VERSION ""

NS_ :

BS_:

BU_: Device Host
VAL_TABLE_ vtSysIgnition 3 "NA" 2 "RESERVED" 1 "ON" 0 "OFF" ;
VAL_TABLE_ vtSysReady 3 "NA" 2 "RESERVED" 1 "READY" 0 "NOT_READY" ;
VAL_TABLE_ vtDtsSysSt 3 "NA" 2 "ERROR" 1 "ON_OK" 0 "OFF" ;
VAL_TABLE_ vtDtsPedlSw 3 "Not available" 2 "Error" 1 "Pedal Depressed" 0 "Pedal Released" ;
VAL_TABLE_ vtOnOff 3 "Not available" 2 "Error" 1 "On" 0 "Off" ;
VAL_TABLE_ vAction_t 3 "va_Take_no_action" 2 "va_Reserved" 1 "va_On" 0 "va_Off" ;
VAL_TABLE_ vtDtsVehDirMov 3 "NA" 2 "REVERSE" 1 "FORWARD" 0 "STANDSTILL" ;

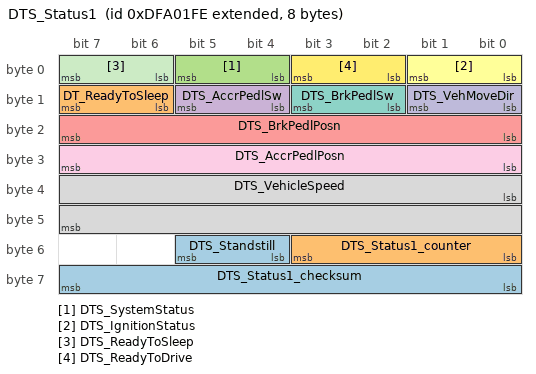
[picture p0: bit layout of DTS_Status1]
BO_ 2381971966 DTS_Status1: 8 Vector__XXX
 SG_ DTS_Standstill : 52|2@1+ (1,0) [0|3] "" Vector__XXX
 SG_ DT_ReadyToSleep : 14|2@1+ (1,0) [0|3] "" Vector__XXX
 SG_ DTS_SystemStatus : 4|2@1+ (1,0) [0|3] "" Vector__XXX
 SG_ DTS_AccrPedlSw : 12|2@1+ (1,0) [0|3] "" Vector__XXX
 SG_ DTS_BrkPedlPosn : 16|8@1+ (0.5,0) [0|127.5] "%" Vector__XXX
 SG_ DTS_IgnitionStatus : 0|2@1+ (1,0) [0|3] "" Vector__XXX
 SG_ DTS_BrkPedlSw : 10|2@1+ (1,0) [0|3] "" Vector__XXX
 SG_ DTS_VehicleSpeed : 32|16@1+ (0.01,-300) [-300|355.35] "km/h" Vector__XXX
 SG_ DTS_AccrPedlPosn : 24|8@1+ (0.4,0) [0|102] "%" Vector__XXX
 SG_ DTS_VehMoveDir : 8|2@1+ (1,0) [0|3] "" Vector__XXX
 SG_ DTS_ReadyToSleep : 6|2@1+ (1,0) [0|3] "" Vector__XXX
 SG_ DTS_ReadyToDrive : 2|2@1+ (1,0) [0|3] "" Vector__XXX
 SG_ DTS_Status1_checksum : 56|8@1+ (1,0) [0|255] "" Vector__XXX
 SG_ DTS_Status1_counter : 48|4@1+ (1,0) [0|15] "" Vector__XXX

CM_ "Arrival Drivetrain Controller Database.
$DBC storage: //depot/auto/dbc/Software_Modules/Drivetrain_Controller/ArrivalDTC/ $
$Change: 0 $
$DateTime: 2020/11/02 14:30:00 $
$Revision: #1 $
$Author: lyamin@arrival.com $
";
CM_ BO_ 2381971966 "Message with general information about current Drivetrain System state";
CM_ SG_ 2381971966 DTS_Standstill "Is the vehicle stationary or not?";
CM_ SG_ 2381971966 DT_ReadyToSleep "IDU readiness flag";
CM_ SG_ 2381971966 DTS_SystemStatus "Drivetrain readiness flag";
CM_ SG_ 2381971966 DTS_AccrPedlSw "is accelerator pedal pressed";
CM_ SG_ 2381971966 DTS_BrkPedlPosn "is brake pedal pressed";
CM_ SG_ 2381971966 DTS_IgnitionStatus "KL15 Ignition line state";
CM_ SG_ 2381971966 DTS_BrkPedlSw "Drivetrain system status";
CM_ SG_ 2381971966 DTS_VehicleSpeed "Signed Vehicle Speed";
CM_ SG_ 2381971966 DTS_VehMoveDir "Vehicle Directionv Movement state";
CM_ SG_ 2381971966 DTS_ReadyToSleep "Drivetrain readiness flag";
CM_ SG_ 2381971966 DTS_ReadyToDrive "Drivetrain readiness flag";
BA_DEF_  "BusType" STRING ;
BA_DEF_  "DBName" STRING ;
BA_DEF_  "DatabaseVersion" STRING ;
BA_DEF_ BO_  "GenMsgCycleTime" INT 0 3600000;
BA_DEF_ BO_  "GenMsgILSupport" ENUM  "No","Yes";
BA_DEF_ BO_  "GenMsgRequestable" INT 0 1;
BA_DEF_ BO_  "GenMsgSendType" ENUM  "cyclic","NotUsed","NotUsed","NotUsed","NotUsed","NotUsed","NotUsed","IfActive","noMsgSendType";
BA_DEF_ SG_  "GenSigEVName" STRING ;
BA_DEF_ SG_  "GenSigILSupport" ENUM  "No","Yes";
BA_DEF_ SG_  "GenSigSendType" ENUM  "Cyclic","OnWrite","OnWriteWithRepetition","OnChange","OnChangeWithRepetition","IfActive","IfActiveWithRepetition","NoSigSendType";
BA_DEF_ SG_  "GenSigStartValue" INT 0 2147483647;
BA_DEF_ BU_  "NmStationAddress" INT 0 255;
BA_DEF_  "ProtocolType" STRING ;
BA_DEF_  "SAE_J1939_21_SpecVersion" STRING ;
BA_DEF_  "SAE_J1939_71_SpecVersion" STRING ;
BA_DEF_  "SAE_J1939_73_SpecVersion" STRING ;
BA_DEF_  "SAE_J1939_75_SpecVersion" STRING ;
BA_DEF_  "SAE_J1939_81_SpecVersion" STRING ;
BA_DEF_  "SAE_J1939_DA_SpecVersion" STRING ;
BA_DEF_ SG_  "SigType" ENUM  "Default","Range","RangeSigned","ASCII","Discrete","Control","ReferencePGN","DTC","StringDelimiter","StringLength","StringLengthControl","MessageCounter","MessageChecksum";
BA_DEF_ BO_  "VFrameFormat" ENUM  "StandardCAN","ExtendedCAN","reserved","J1939PG","reserved","reserved","reserved","reserved","reserved","reserved","reserved","reserved","reserved","reserved","StandardCAN_FD","ExtendedCAN_FD";
BA_DEF_DEF_  "BusType" "";
BA_DEF_DEF_  "DBName" "";
BA_DEF_DEF_  "DatabaseVersion" "";
BA_DEF_DEF_  "GenMsgCycleTime" 0;
BA_DEF_DEF_  "GenMsgILSupport" "Yes";
BA_DEF_DEF_  "GenMsgRequestable" 1;
BA_DEF_DEF_  "GenMsgSendType" "noMsgSendType";
BA_DEF_DEF_  "GenSigEVName" "Env@Nodename_@Signame";
BA_DEF_DEF_  "GenSigILSupport" "Yes";
BA_DEF_DEF_  "GenSigSendType" "NoSigSendType";
BA_DEF_DEF_  "GenSigStartValue" 0;
BA_DEF_DEF_  "NmStationAddress" 254;
BA_DEF_DEF_  "ProtocolType" "";
BA_DEF_DEF_  "SAE_J1939_21_SpecVersion" "";
BA_DEF_DEF_  "SAE_J1939_71_SpecVersion" "";
BA_DEF_DEF_  "SAE_J1939_73_SpecVersion" "";
BA_DEF_DEF_  "SAE_J1939_75_SpecVersion" "";
BA_DEF_DEF_  "SAE_J1939_81_SpecVersion" "";
BA_DEF_DEF_  "SAE_J1939_DA_SpecVersion" "";
BA_DEF_DEF_  "SigType" "Default";
BA_DEF_DEF_  "VFrameFormat" "J1939PG";
BA_ "SAE_J1939_DA_SpecVersion" "2015-01";
BA_ "SAE_J1939_81_SpecVersion" "2012-05";
BA_ "SAE_J1939_75_SpecVersion" "2012-05";
BA_ "SAE_J1939_73_SpecVersion" "2012-10";
BA_ "SAE_J1939_71_SpecVersion" "2012-10";
BA_ "SAE_J1939_21_SpecVersion" "2006-10";
BA_ "ProtocolType" "J1939";
BA_ "DatabaseVersion" "1.0";
BA_ "BusType" "CAN";
BA_ "DBName" "DTS_Status1";
BA_ "GenMsgCycleTime" BO_ 2381971966 50;
BA_ "GenMsgSendType" BO_ 2381971966 0;
BA_ "SigType" SG_ 2381971966 DTS_BrkPedlPosn 1;
BA_ "SigType" SG_ 2381971966 DTS_VehicleSpeed 1;
BA_ "GenSigStartValue" SG_ 2381971966 DTS_VehicleSpeed 30000;
BA_ "SigType" SG_ 2381971966 DTS_AccrPedlPosn 1;
BA_ "SigType" SG_ 2381971966 DTS_Status1_checksum 12;
BA_ "GenSigSendType" SG_ 2381971966 DTS_Status1_checksum 0;
BA_ "GenSigSendType" SG_ 2381971966 DTS_Status1_counter 0;
BA_ "SigType" SG_ 2381971966 DTS_Status1_counter 11;
VAL_ 2381971966 DTS_Standstill 3 "NA" 2 "RESERVE" 1 "MOVING" 0 "STANDSTILL" ;
VAL_ 2381971966 DT_ReadyToSleep 3 "NA" 2 "RESERVED" 1 "READY" 0 "NOT_READY" ;
VAL_ 2381971966 DTS_SystemStatus 3 "Not available" 2 "Error" 1 "On" 0 "Off" ;
VAL_ 2381971966 DTS_AccrPedlSw 3 "Not available" 2 "Error" 1 "Pedal Depressed" 0 "Pedal Released" ;
VAL_ 2381971966 DTS_IgnitionStatus 3 "NA" 2 "RESERVED" 1 "ON" 0 "OFF" ;
VAL_ 2381971966 DTS_BrkPedlSw 3 "Not available" 2 "Error" 1 "Pedal Depressed" 0 "Pedal Released" ;
VAL_ 2381971966 DTS_VehMoveDir 3 "NA" 2 "REVERSE" 1 "FORWARD" 0 "STANDSTILL" ;
VAL_ 2381971966 DTS_ReadyToSleep 3 "NA" 2 "RESERVED" 1 "READY" 0 "NOT_READY" ;
VAL_ 2381971966 DTS_ReadyToDrive 3 "NA" 2 "RESERVED" 1 "READY" 0 "NOT_READY" ;
